# ISD9300_v3 register map
File version: 1.0
Registers are 32-bit, read-write, reset 0x0 unless marked. A register's access mark holds for its fields unless they carry their own. Offsets are from the block's base; [hi:lo] are bit positions; {n}, {i} and the like mark numbered series.

## ACMP — ACMP Register Map
Base 0x400D0000
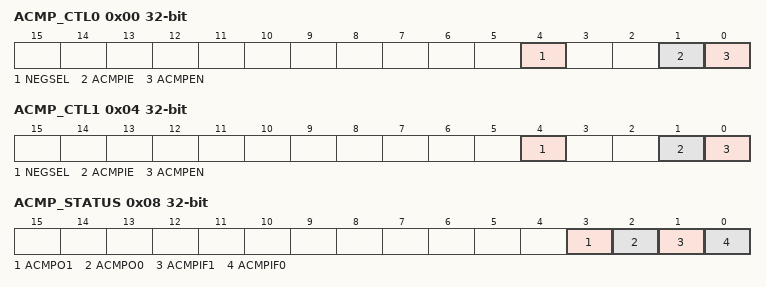
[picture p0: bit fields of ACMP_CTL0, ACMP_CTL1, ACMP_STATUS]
0x00 ACMP_CTL0 — Analog Comparator 0 Control Register
  [4] NEGSEL — Comparator0 Negative Input Select
    0=VBG, Bandgap reference voltage aaa 1.2V; 1=VMID reference voltage aaa VCCA/2
  [1] ACMPIE — CMP0 Interrupt Enable
    0=Disable CMP0 interrupt function; 1=Enable CMP0 interrupt function
  [0] ACMPEN — Comparator Enable
    0=Disable; 1=Enable
0x04 ACMP_CTL1 — Analog Comparator 1 Control Register
  [4] NEGSEL — Comparator1 Negative Input Select
    0=GPIOB[7]; 1=VBG, Bandgap reference voltage aaa 1.2V
  [1] ACMPIE — CMP1 Interrupt Enable
    0=Disable CMP1interrupt function; 1=Enable CMP1 interrupt function
  [0] ACMPEN — Comparator Enable
    0=Disable; 1=Enable
0x08 ACMP_STATUS (reset mask 0xFFFFFF00) — Comparator Status Register
  [3] ACMPO1 — Comparator1 Output. Synchronized to the APB clock to allow reading by software. Cleared when the comparator is disabled (CMP1EN aaa 0).
  [2] ACMPO0 — Comparator0 Output. Synchronized to the APB clock to allow reading by software. Cleared when the comparator is disabled (CMP0EN aaa 0).
  [1] ACMPIF1 — Compare 1 Flag. This bit is set by hardware whenever the comparator output changes state. This bit will cause a hardware interrupt if enabled. This bit is cleared by writing 1 to itself.
  [0] ACMPIF0 — Compare 0 Flag. This bit is set by hardware whenever the comparator output changes state. This bit will cause a hardware interrupt if enabled. This bit is cleared by writing 1 to itself.
0x0C ACMP_POSSEL — Comparator Select Register
  [2:0] POSSEL — Comparator0 GPIO Selection. GPIOB[POSSEL] is the active analog GPIO input selected to Comparator 0 positive input.

## ALC — ALC Register Map
Base 0x400B0048
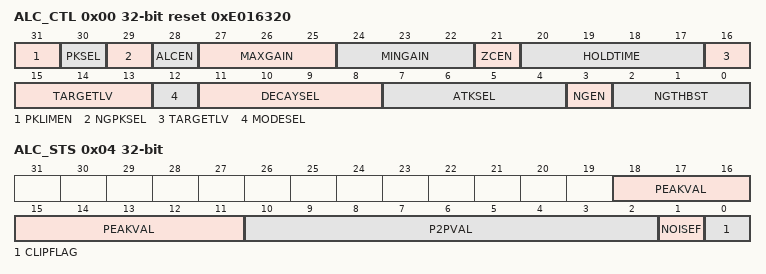
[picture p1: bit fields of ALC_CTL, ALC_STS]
0x00 ALC_CTL reset 0xE016320 — ALC Control Register
  [31] PKLIMEN — ALC Peak Limiter Enable
    0=enable fast decrement when signal exceeds 87.5% of full scale (default); 1=disable fast decrement when signal exceeds 87.5% of full scale
  [30] PKSEL — ALC Gain Peak Detector Select
    0=use absolute peak value for ALC training (default); 1=use peak-to-peak value for ALC training
  [29] NGPKSEL — ALC Noise Gate Peak Detector Select
    0=use peak-to-peak value for noise gate threshold determination (default); 1=use absolute peak value for noise gate threshold determination
  [28] ALCEN — ALC Select
    0=ALC disabled (default); 1=ALC enabled
  [27:25] MAXGAIN — ALC Maximum Gain
    0=-6.75 dB; 1=-0.75 dB; 2=+5.25 dB; 3=+11.25 dB; 4=+17.25 dB; 5=+23.25 dB; 6=+29.25 dB; 7=+35.25 dB
  [24:22] MINGAIN — ALC Minimum Gain
    0=-12 dB; 1=-6 dB; 2=0 dB; 3=6 dB; 4=12 dB; 5=18 dB; 6=24 dB; 7=30 dB
  [21] ZCEN — ALC Zero Crossing
    0=zero crossing disabled; 1=zero crossing enabled
  [20:17] HOLDTIME — ALC Hold Time (Value: 0~10). Hold Time aaa (2^HOLDTIME) ms
  [16:13] TARGETLV — ALC Target Level
    0=-28.5 dB; 1=-27 dB; 2=-25.5 dB; 3=-24 dB; 4=-22.5 dB; 5=-21 dB; 6=-19.5 dB; 7=-18 dB; 8=-16.5 dB; 9=-15 dB; 10=-13.5 dB; 11=-12 dB; 12=-10.5 dB; 13=-9 dB; 14=-7.5 dB; 15=-6 dB
  [12] MODESEL — ALC Mode
    0=ALC normal operation mode; 1=ALC limiter mode
  [11:8] DECAYSEL — ALC Decay Time (Value: 0~10). When MODESEL aaa 0, Range: 125us to 128ms. When MODESEL aaa 1, Range: 31us to 32ms (time doubles with every step)
  [7:4] ATKSEL — ALC Attack Time (Value: 0~10). When MODESEL aaa 0, Range: 500us to 512ms. When MODESEL aaa 1,Range: 125us to 128ms (Both ALC time doubles with every step)
  [3] NGEN — Noise Gate Enable
    0=Noise gate disabled; 1=Noise gate enabled
  [2:0] NGTHBST — Noise Gate Threshold. Boost disabled: Threshold aaa (-81+6xNGTHBST) dB. Boost enabled: Threshold aaa (-87+6xNGTHBST) dB
0x04 ALC_STS ro — ALC status register
  [18:11] PEAKVAL — Peak Value. 9 MSBs of measured absolute peak value
  [10:2] P2PVAL — Peak-To-Peak Value. 9 MSBs of measured peak-to-peak value
  [1] NOISEF — Noise Flag. Asserted when signal level is detected to be below NGTH
  [0] CLIPFLAG — Clipping Flag. Asserted when signal level is detected to be above 87.5% of full scale
0x08 ALC_INTSTS — ALC interrupt register
  [0] INTFLAG — ALC Interrupt. This interrupt flag asserts whenever the interrupt is enabled and the PGA gain is updated, either through an ALC change with the ALC enabled or through a PGA gain write with the ALC disabled. Write a 1 to this register to clear.
0x0C ALC_INTCTL — ALC interrupt enable register
  [0] INTEN — ALC Interrupt Enable
    0=INTEN disabled; 1=INTEN enabled

## BIQ — BIQ Register Map
Base 0x400B0000
{0x0+4i} BIQ_COEFF{i} reset 0xD010 (i=0..14) — Coefficient b0 In H(z) Transfer Function (3.16 format) - 1st stage BIQ Coefficients
  [31:0] COEFFDAT — Coefficient Data
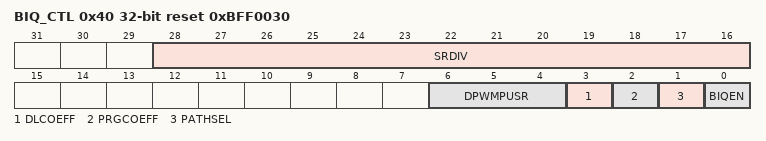
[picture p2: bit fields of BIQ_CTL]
0x40 BIQ_CTL reset 0xBFF0030 — BIQ Control Register
  [28:16] SRDIV — Sample Rate Divider. This register is used to program the operating sampling rate of the biquad filter. The sample rate is defined as. HCLK/(SRDIV+1). Default to 3071 so the sampling rate is 16K when HCLK is 49.152MHz.
  [6:4] DPWMPUSR — DPWM Path Up Sample Rate (From SRDIV Result). This register is only used when PATHSEL is set to 1. The operating sample rate for the biquad filter will be (DPWMPUSR+1)*HCLK/(SRDIV+1). Default value for this register is 3.
  [3] DLCOEFF — Move BIQ Out Of Reset State
    0=BIQ filter is in reset state; 1=When this bit is on, the default coefficients will be downloaded to the coefficient ram automatically in 32 internal system clocks. Processor must delay enough time before changing the coefficients or turn the BIQ on
  [2] PRGCOEFF — Programming Mode Coefficient Control Bit. This bit must be turned off when BIQEN in on.
    0=Coefficient RAM is in normal mode; 1=coefficient RAM is under programming mode
  [1] PATHSEL — AC Path Selection For BIQ
    0=used in ADC path; 1=used in DPWM path
  [0] BIQEN — BIQ Filter Start To Run
    0=BIQ filter is not processing; 1=BIQ filter is on
